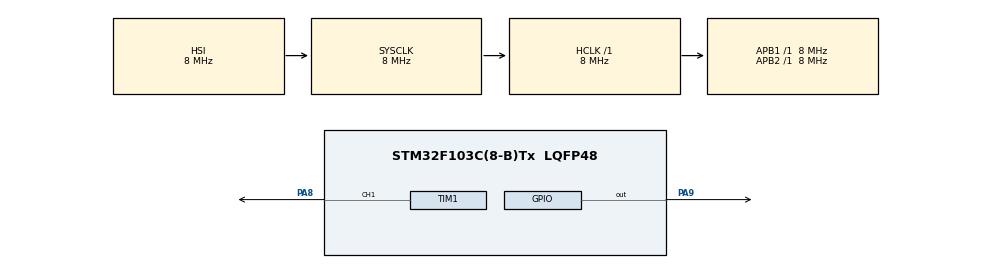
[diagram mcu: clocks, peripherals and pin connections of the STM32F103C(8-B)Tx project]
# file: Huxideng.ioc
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Mcu.Family=STM32F1
Mcu.Name=STM32F103C(8-B)Tx
Mcu.Package=LQFP48
NVIC.PriorityGroup=NVIC_PRIORITYGROUP_4
PA13.Mode=Serial_Wire
PA13.Signal=SYS_JTMS-SWDIO
PA14.Mode=Serial_Wire
PA14.Signal=SYS_JTCK-SWCLK
PA8.Signal=S_TIM1_CH1
PA9.PinState=GPIO_PIN_SET
PA9.Signal=GPIO_Output
ProjectManager.HeapSize=0x200
ProjectManager.StackSize=0x400
ProjectManager.TargetToolchain=MDK-ARM V5.32
RCC.AHBFreq_Value=8000000
RCC.APB1Freq_Value=8000000
RCC.APB1TimFreq_Value=8000000
RCC.APB2Freq_Value=8000000
RCC.APB2TimFreq_Value=8000000
RCC.HCLKFreq_Value=8000000
RCC.SYSCLKFreq_VALUE=8000000
RCC.USBFreq_Value=8000000
SH.S_TIM1_CH1.0=TIM1_CH1,PWM Generation1 CH1
TIM1.AutoReloadPreload=TIM_AUTORELOAD_PRELOAD_ENABLE
TIM1.Channel-PWM\ Generation1\ CH1=TIM_CHANNEL_1
TIM1.Period=999
TIM1.Prescaler=7
VP_TIM1_VS_ClockSourceINT.Mode=Internal
board=custom

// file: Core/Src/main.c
/* USER CODE BEGIN Header */
/**
  ******************************************************************************
  * @file           : main.c
  * @brief          : Main program body
  ******************************************************************************
  * @attention
  *
  * Copyright (c) 2025 STMicroelectronics.
  * All rights reserved.
  *
  * This software is licensed under terms that can be found in the LICENSE file
  * in the root directory of this software component.
  * If no LICENSE file comes with this software, it is provided AS-IS.
  *
  ******************************************************************************
  */
/* USER CODE END Header */
#include "main.h"
#include "tim.h"
#include "gpio.h"

/* USER CODE BEGIN Includes */
#include "math.h"
/* USER CODE END Includes */

void SystemClock_Config(void);

/* USER CODE BEGIN 0 */

uint8_t pwm_duty = 40;  // PWM占空比 (0-100%)

/* USER CODE END 0 */

int main(void)
{

  /* MCU Configuration--------------------------------------------------------*/

  /* Reset of all peripherals, Initializes the Flash interface and the Systick. */
  HAL_Init();

  /* Configure the system clock */
  SystemClock_Config();

  /* Initialize all configured peripherals */
  MX_GPIO_Init();
  MX_TIM1_Init();
  /* USER CODE BEGIN 2 */

  // 启动PWM
  HAL_TIM_PWM_Start(&htim1, TIM_CHANNEL_1);

  // 设置初始占空比为0
  __HAL_TIM_SET_COMPARE(&htim1, TIM_CHANNEL_1, 0);
  /* USER CODE END 2 */

  /* Infinite loop */
  while (1)
  {

    /* USER CODE BEGIN 3 */

		if (HAL_GPIO_ReadPin(GPIOA, GPIO_PIN_9) == GPIO_PIN_RESET)
    {
      HAL_Delay(10);  // 消抖
      if (HAL_GPIO_ReadPin(GPIOA, GPIO_PIN_9) == GPIO_PIN_RESET)
      {
        // 增加PWM占空比
        pwm_duty += 20;
        if (pwm_duty > 100)
        {
          pwm_duty = 40;
        }
				  // 更新PWM输出
        uint32_t pulse = (htim1.Instance->ARR * pwm_duty) / 100;
        __HAL_TIM_SET_COMPARE(&htim1, TIM_CHANNEL_1, pulse);
			}
			while (HAL_GPIO_ReadPin(GPIOA, GPIO_PIN_9) == GPIO_PIN_RESET);
		}

	}
  /* USER CODE END 3 */
}

void SystemClock_Config(void)
{
  RCC_OscInitTypeDef RCC_OscInitStruct = {0};
  RCC_ClkInitTypeDef RCC_ClkInitStruct = {0};

  /** Initializes the RCC Oscillators according to the specified parameters
  * in the RCC_OscInitTypeDef structure.
  */
  RCC_OscInitStruct.OscillatorType = RCC_OSCILLATORTYPE_HSI;
  RCC_OscInitStruct.HSIState = RCC_HSI_ON;
  RCC_OscInitStruct.HSICalibrationValue = RCC_HSICALIBRATION_DEFAULT;
  RCC_OscInitStruct.PLL.PLLState = RCC_PLL_NONE;
  if (HAL_RCC_OscConfig(&RCC_OscInitStruct) != HAL_OK)
  {
    Error_Handler();
  }

  /** Initializes the CPU, AHB and APB buses clocks
  */
  RCC_ClkInitStruct.ClockType = RCC_CLOCKTYPE_HCLK|RCC_CLOCKTYPE_SYSCLK
                              |RCC_CLOCKTYPE_PCLK1|RCC_CLOCKTYPE_PCLK2;
  RCC_ClkInitStruct.SYSCLKSource = RCC_SYSCLKSOURCE_HSI;
  RCC_ClkInitStruct.AHBCLKDivider = RCC_SYSCLK_DIV1;
  RCC_ClkInitStruct.APB1CLKDivider = RCC_HCLK_DIV1;
  RCC_ClkInitStruct.APB2CLKDivider = RCC_HCLK_DIV1;

  if (HAL_RCC_ClockConfig(&RCC_ClkInitStruct, FLASH_LATENCY_0) != HAL_OK)
  {
    Error_Handler();
  }
}

void Error_Handler(void)
{
  __disable_irq();
  while (1)
  {
  }
}
